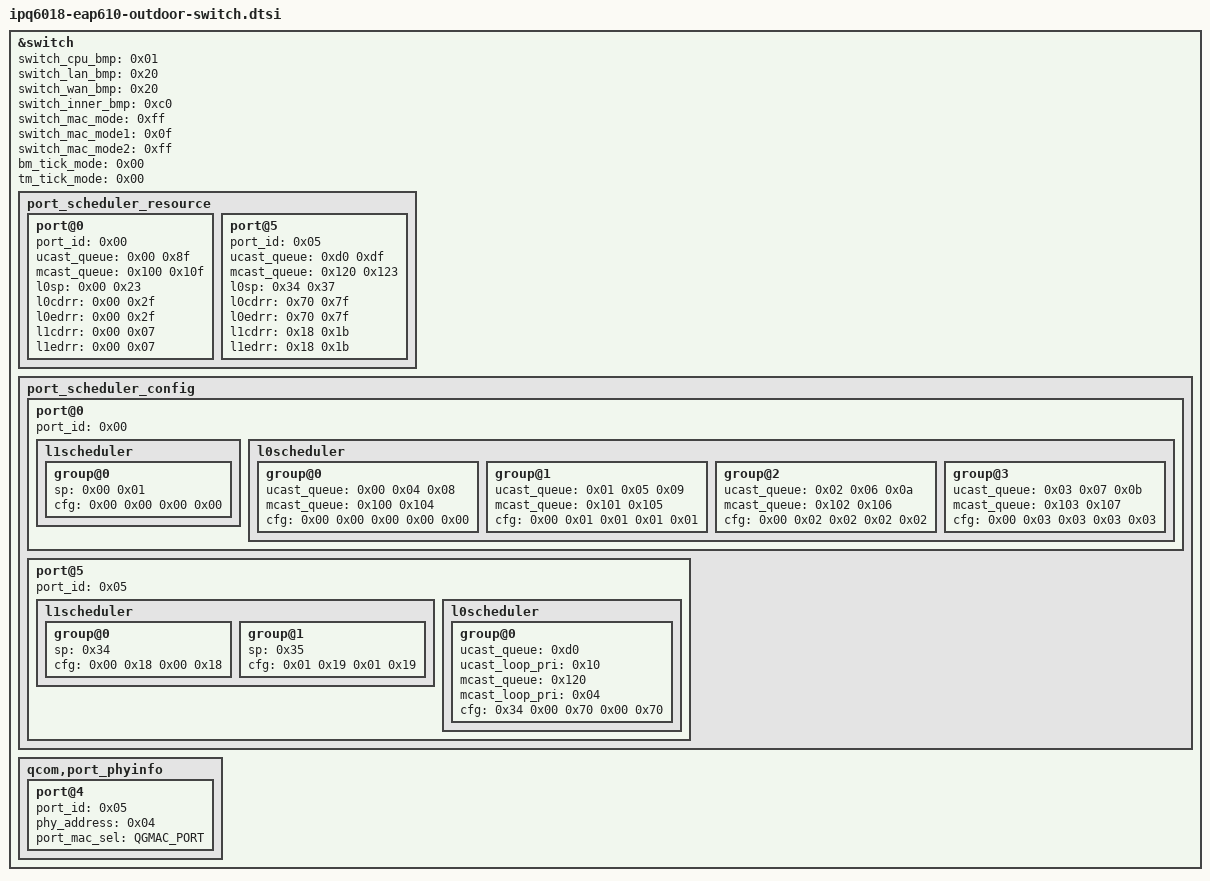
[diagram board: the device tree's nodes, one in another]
#include "ipq6018-ess.dtsi"

&switch {
	status = "okay";

	switch_cpu_bmp = <0x01>;
	switch_lan_bmp = <0x20>;
	switch_wan_bmp = <0x20>;
	switch_inner_bmp = <0xc0>;
	switch_mac_mode = <0xff>;
	switch_mac_mode1 = <0x0f>;
	switch_mac_mode2 = <0xff>;
	bm_tick_mode = <0x00>;
	tm_tick_mode = <0x00>;

	port_scheduler_resource {
		port@0 {
			port_id = <0x00>;
			ucast_queue = <0x00 0x8f>;
			mcast_queue = <0x100 0x10f>;
			l0sp = <0x00 0x23>;
			l0cdrr = <0x00 0x2f>;
			l0edrr = <0x00 0x2f>;
			l1cdrr = <0x00 0x07>;
			l1edrr = <0x00 0x07>;
		};

		port@5 {
			port_id = <0x05>;
			ucast_queue = <0xd0 0xdf>;
			mcast_queue = <0x120 0x123>;
			l0sp = <0x34 0x37>;
			l0cdrr = <0x70 0x7f>;
			l0edrr = <0x70 0x7f>;
			l1cdrr = <0x18 0x1b>;
			l1edrr = <0x18 0x1b>;
		};
	};

	port_scheduler_config {
		port@0 {
			port_id = <0x00>;

			l1scheduler {
				group@0 {
					sp = <0x00 0x01>;
					cfg = <0x00 0x00 0x00 0x00>;
				};
			};

			l0scheduler {
				group@0 {
					ucast_queue = <0x00 0x04 0x08>;
					mcast_queue = <0x100 0x104>;
					cfg = <0x00 0x00 0x00 0x00 0x00>;
				};

				group@1 {
					ucast_queue = <0x01 0x05 0x09>;
					mcast_queue = <0x101 0x105>;
					cfg = <0x00 0x01 0x01 0x01 0x01>;
				};

				group@2 {
					ucast_queue = <0x02 0x06 0x0a>;
					mcast_queue = <0x102 0x106>;
					cfg = <0x00 0x02 0x02 0x02 0x02>;
				};

				group@3 {
					ucast_queue = <0x03 0x07 0x0b>;
					mcast_queue = <0x103 0x107>;
					cfg = <0x00 0x03 0x03 0x03 0x03>;
				};
			};
		};


		port@5 {
			port_id = <0x05>;

			l1scheduler {
				group@0 {
					sp = <0x34>;
					cfg = <0x00 0x18 0x00 0x18>;
				};

				group@1 {
					sp = <0x35>;
					cfg = <0x01 0x19 0x01 0x19>;
				};
			};

			l0scheduler {
				group@0 {
					ucast_queue = <0xd0>;
					ucast_loop_pri = <0x10>;
					mcast_queue = <0x120>;
					mcast_loop_pri = <0x04>;
					cfg = <0x34 0x00 0x70 0x00 0x70>;
				};
			};
		};
	};

	qcom,port_phyinfo {
		port@4 {
			port_id = <0x05>;
			phy_address = <0x04>;
			port_mac_sel = "QGMAC_PORT";
		};
	};
};
